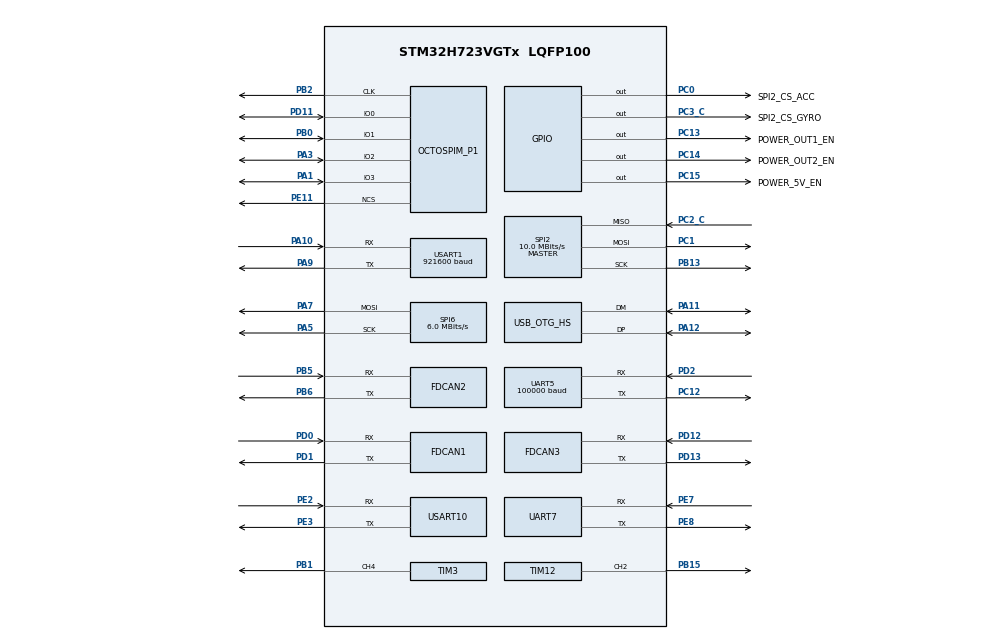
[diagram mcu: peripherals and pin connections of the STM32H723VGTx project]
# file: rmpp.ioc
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CORTEX_M7.CPU_DCache=Enabled
CORTEX_M7.CPU_ICache=Enabled
CORTEX_M7.default_mode_Activation=0
Dma.DMA_GENERATOR0.7.Direction=DMA_MEMORY_TO_PERIPH
Dma.DMA_GENERATOR0.7.EventEnable=DISABLE
Dma.DMA_GENERATOR0.7.FIFOMode=DMA_FIFOMODE_DISABLE
Dma.DMA_GENERATOR0.7.Instance=DMA2_Stream0
Dma.DMA_GENERATOR0.7.MemDataAlignment=DMA_MDATAALIGN_HALFWORD
Dma.DMA_GENERATOR0.7.MemInc=DMA_MINC_ENABLE
Dma.DMA_GENERATOR0.7.Mode=DMA_CIRCULAR
Dma.DMA_GENERATOR0.7.PeriphDataAlignment=DMA_PDATAALIGN_HALFWORD
Dma.DMA_GENERATOR0.7.PeriphInc=DMA_PINC_DISABLE
Dma.DMA_GENERATOR0.7.Polarity=HAL_DMAMUX_REQ_GEN_RISING
Dma.DMA_GENERATOR0.7.Priority=DMA_PRIORITY_LOW
Dma.DMA_GENERATOR0.7.RequestNumber=1
Dma.DMA_GENERATOR0.7.SignalID=HAL_DMAMUX1_REQ_GEN_TIM12_TRGO
Dma.DMA_GENERATOR0.7.SyncEnable=DISABLE
Dma.DMA_GENERATOR0.7.SyncPolarity=HAL_DMAMUX_SYNC_NO_EVENT
Dma.DMA_GENERATOR0.7.SyncRequestNumber=1
Dma.DMA_GENERATOR0.7.SyncSignalID=NONE
Dma.Request0=UART5_RX
Dma.Request1=USART1_RX
Dma.Request2=USART1_TX
Dma.Request3=UART7_RX
Dma.Request4=UART7_TX
Dma.Request5=USART10_RX
Dma.Request6=USART10_TX
Dma.Request7=DMA_GENERATOR0
Dma.UART5_RX.0.Direction=DMA_PERIPH_TO_MEMORY
Dma.UART5_RX.0.EventEnable=DISABLE
Dma.UART5_RX.0.FIFOMode=DMA_FIFOMODE_DISABLE
Dma.UART5_RX.0.Instance=DMA1_Stream0
Dma.UART5_RX.0.MemDataAlignment=DMA_MDATAALIGN_BYTE
Dma.UART5_RX.0.MemInc=DMA_MINC_ENABLE
Dma.UART5_RX.0.Mode=DMA_NORMAL
Dma.UART5_RX.0.PeriphDataAlignment=DMA_PDATAALIGN_BYTE
Dma.UART5_RX.0.PeriphInc=DMA_PINC_DISABLE
Dma.UART5_RX.0.Polarity=HAL_DMAMUX_REQ_GEN_RISING
Dma.UART5_RX.0.Priority=DMA_PRIORITY_LOW
Dma.UART5_RX.0.RequestNumber=1
Dma.UART5_RX.0.SignalID=NONE
Dma.UART5_RX.0.SyncEnable=DISABLE
Dma.UART5_RX.0.SyncPolarity=HAL_DMAMUX_SYNC_NO_EVENT
Dma.UART5_RX.0.SyncRequestNumber=1
Dma.UART5_RX.0.SyncSignalID=NONE
Dma.UART7_RX.3.Direction=DMA_PERIPH_TO_MEMORY
Dma.UART7_RX.3.EventEnable=DISABLE
Dma.UART7_RX.3.FIFOMode=DMA_FIFOMODE_DISABLE
Dma.UART7_RX.3.Instance=DMA1_Stream3
Dma.UART7_RX.3.MemDataAlignment=DMA_MDATAALIGN_BYTE
Dma.UART7_RX.3.MemInc=DMA_MINC_ENABLE
Dma.UART7_RX.3.Mode=DMA_NORMAL
Dma.UART7_RX.3.PeriphDataAlignment=DMA_PDATAALIGN_BYTE
Dma.UART7_RX.3.PeriphInc=DMA_PINC_DISABLE
Dma.UART7_RX.3.Polarity=HAL_DMAMUX_REQ_GEN_RISING
Dma.UART7_RX.3.Priority=DMA_PRIORITY_LOW
Dma.UART7_RX.3.RequestNumber=1
Dma.UART7_RX.3.SignalID=NONE
Dma.UART7_RX.3.SyncEnable=DISABLE
Dma.UART7_RX.3.SyncPolarity=HAL_DMAMUX_SYNC_NO_EVENT
Dma.UART7_RX.3.SyncRequestNumber=1
Dma.UART7_RX.3.SyncSignalID=NONE
Dma.UART7_TX.4.Direction=DMA_MEMORY_TO_PERIPH
Dma.UART7_TX.4.EventEnable=DISABLE
Dma.UART7_TX.4.FIFOMode=DMA_FIFOMODE_DISABLE
Dma.UART7_TX.4.Instance=DMA1_Stream4
Dma.UART7_TX.4.MemDataAlignment=DMA_MDATAALIGN_BYTE
Dma.UART7_TX.4.MemInc=DMA_MINC_ENABLE
Dma.UART7_TX.4.Mode=DMA_NORMAL
Dma.UART7_TX.4.PeriphDataAlignment=DMA_PDATAALIGN_BYTE
Dma.UART7_TX.4.PeriphInc=DMA_PINC_DISABLE
Dma.UART7_TX.4.Polarity=HAL_DMAMUX_REQ_GEN_RISING
Dma.UART7_TX.4.Priority=DMA_PRIORITY_LOW
Dma.UART7_TX.4.RequestNumber=1
Dma.UART7_TX.4.SignalID=NONE
Dma.UART7_TX.4.SyncEnable=DISABLE
Dma.UART7_TX.4.SyncPolarity=HAL_DMAMUX_SYNC_NO_EVENT
Dma.UART7_TX.4.SyncRequestNumber=1
Dma.UART7_TX.4.SyncSignalID=NONE
Dma.USART10_RX.5.Direction=DMA_PERIPH_TO_MEMORY
Dma.USART10_RX.5.EventEnable=DISABLE
Dma.USART10_RX.5.FIFOMode=DMA_FIFOMODE_DISABLE
Dma.USART10_RX.5.Instance=DMA1_Stream5
Dma.USART10_RX.5.MemDataAlignment=DMA_MDATAALIGN_BYTE
Dma.USART10_RX.5.MemInc=DMA_MINC_ENABLE
Dma.USART10_RX.5.Mode=DMA_NORMAL
Dma.USART10_RX.5.PeriphDataAlignment=DMA_PDATAALIGN_BYTE
Dma.USART10_RX.5.PeriphInc=DMA_PINC_DISABLE
Dma.USART10_RX.5.Polarity=HAL_DMAMUX_REQ_GEN_RISING
Dma.USART10_RX.5.Priority=DMA_PRIORITY_LOW
Dma.USART10_RX.5.RequestNumber=1
Dma.USART10_RX.5.SignalID=NONE
Dma.USART10_RX.5.SyncEnable=DISABLE
Dma.USART10_RX.5.SyncPolarity=HAL_DMAMUX_SYNC_NO_EVENT
Dma.USART10_RX.5.SyncRequestNumber=1
Dma.USART10_RX.5.SyncSignalID=NONE
Dma.USART10_TX.6.Direction=DMA_MEMORY_TO_PERIPH
Dma.USART10_TX.6.EventEnable=DISABLE
Dma.USART10_TX.6.FIFOMode=DMA_FIFOMODE_DISABLE
Dma.USART10_TX.6.Instance=DMA1_Stream6
Dma.USART10_TX.6.MemDataAlignment=DMA_MDATAALIGN_BYTE
Dma.USART10_TX.6.MemInc=DMA_MINC_ENABLE
Dma.USART10_TX.6.Mode=DMA_NORMAL
Dma.USART10_TX.6.PeriphDataAlignment=DMA_PDATAALIGN_BYTE
Dma.USART10_TX.6.PeriphInc=DMA_PINC_DISABLE
Dma.USART10_TX.6.Polarity=HAL_DMAMUX_REQ_GEN_RISING
Dma.USART10_TX.6.Priority=DMA_PRIORITY_LOW
Dma.USART10_TX.6.RequestNumber=1
Dma.USART10_TX.6.SignalID=NONE
Dma.USART10_TX.6.SyncEnable=DISABLE
Dma.USART10_TX.6.SyncPolarity=HAL_DMAMUX_SYNC_NO_EVENT
Dma.USART10_TX.6.SyncRequestNumber=1
Dma.USART10_TX.6.SyncSignalID=NONE
Dma.USART1_RX.1.Direction=DMA_PERIPH_TO_MEMORY
Dma.USART1_RX.1.EventEnable=DISABLE
Dma.USART1_RX.1.FIFOMode=DMA_FIFOMODE_DISABLE
Dma.USART1_RX.1.Instance=DMA1_Stream1
Dma.USART1_RX.1.MemDataAlignment=DMA_MDATAALIGN_BYTE
Dma.USART1_RX.1.MemInc=DMA_MINC_ENABLE
Dma.USART1_RX.1.Mode=DMA_NORMAL
Dma.USART1_RX.1.PeriphDataAlignment=DMA_PDATAALIGN_BYTE
Dma.USART1_RX.1.PeriphInc=DMA_PINC_DISABLE
Dma.USART1_RX.1.Polarity=HAL_DMAMUX_REQ_GEN_RISING
Dma.USART1_RX.1.Priority=DMA_PRIORITY_LOW
Dma.USART1_RX.1.RequestNumber=1
Dma.USART1_RX.1.SignalID=NONE
Dma.USART1_RX.1.SyncEnable=DISABLE
Dma.USART1_RX.1.SyncPolarity=HAL_DMAMUX_SYNC_NO_EVENT
Dma.USART1_RX.1.SyncRequestNumber=1
Dma.USART1_RX.1.SyncSignalID=NONE
Dma.USART1_TX.2.Direction=DMA_MEMORY_TO_PERIPH
Dma.USART1_TX.2.EventEnable=DISABLE
Dma.USART1_TX.2.FIFOMode=DMA_FIFOMODE_DISABLE
Dma.USART1_TX.2.Instance=DMA1_Stream2
Dma.USART1_TX.2.MemDataAlignment=DMA_MDATAALIGN_BYTE
Dma.USART1_TX.2.MemInc=DMA_MINC_ENABLE
Dma.USART1_TX.2.Mode=DMA_NORMAL
Dma.USART1_TX.2.PeriphDataAlignment=DMA_PDATAALIGN_BYTE
Dma.USART1_TX.2.PeriphInc=DMA_PINC_DISABLE
Dma.USART1_TX.2.Polarity=HAL_DMAMUX_REQ_GEN_RISING
Dma.USART1_TX.2.Priority=DMA_PRIORITY_LOW
Dma.USART1_TX.2.RequestNumber=1
Dma.USART1_TX.2.SignalID=NONE
Dma.USART1_TX.2.SyncEnable=DISABLE
Dma.USART1_TX.2.SyncPolarity=HAL_DMAMUX_SYNC_NO_EVENT
Dma.USART1_TX.2.SyncRequestNumber=1
Dma.USART1_TX.2.SyncSignalID=NONE
FDCAN1.AutoRetransmission=ENABLE
FDCAN1.CalculateBaudRateNominal=1000000
FDCAN1.CalculateTimeBitNominal=1000
FDCAN1.CalculateTimeQuantumNominal=40.0
FDCAN1.ExtFiltersNbr=1
FDCAN1.MessageRAMOffset=0x000
FDCAN1.NominalPrescaler=5
FDCAN1.NominalSyncJumpWidth=5
FDCAN1.NominalTimeSeg1=19
FDCAN1.NominalTimeSeg2=5
FDCAN1.RxFifo0ElmtsNbr=32
FDCAN1.StdFiltersNbr=1
FDCAN1.TxBuffersNbr=0
FDCAN1.TxFifoQueueElmtsNbr=32
FDCAN1.TxFifoQueueMode=FDCAN_TX_FIFO_OPERATION
FDCAN2.AutoRetransmission=ENABLE
FDCAN2.CalculateBaudRateNominal=1000000
FDCAN2.CalculateTimeBitNominal=1000
FDCAN2.CalculateTimeQuantumNominal=40.0
FDCAN2.ExtFiltersNbr=1
FDCAN2.MessageRAMOffset=0x358
FDCAN2.NominalPrescaler=5
FDCAN2.NominalSyncJumpWidth=5
FDCAN2.NominalTimeSeg1=19
FDCAN2.NominalTimeSeg2=5
FDCAN2.RxFifo0ElmtsNbr=32
FDCAN2.StdFiltersNbr=1
FDCAN2.TxBuffersNbr=0
FDCAN2.TxFifoQueueElmtsNbr=32
FDCAN2.TxFifoQueueMode=FDCAN_TX_FIFO_OPERATION
FDCAN3.AutoRetransmission=ENABLE
FDCAN3.CalculateBaudRateNominal=1000000
FDCAN3.CalculateTimeBitNominal=1000
FDCAN3.CalculateTimeQuantumNominal=40.0
FDCAN3.ExtFiltersNbr=1
FDCAN3.MessageRAMOffset=0x6B0
FDCAN3.NominalPrescaler=5
FDCAN3.NominalSyncJumpWidth=5
FDCAN3.NominalTimeSeg1=19
FDCAN3.NominalTimeSeg2=5
FDCAN3.RxFifo0ElmtsNbr=32
FDCAN3.StdFiltersNbr=1
FDCAN3.TxFifoQueueElmtsNbr=32
FDCAN3.TxFifoQueueMode=FDCAN_TX_FIFO_OPERATION
Mcu.Family=STM32H7
Mcu.Name=STM32H723VGTx
Mcu.Package=LQFP100
NVIC.DMA1_Stream0_IRQn=true\:0\:0\:false\:false\:true\:false\:true\:true
NVIC.DMA1_Stream1_IRQn=true\:0\:0\:false\:false\:true\:false\:true\:true
NVIC.DMA1_Stream2_IRQn=true\:0\:0\:false\:false\:true\:false\:true\:true
NVIC.DMA1_Stream3_IRQn=true\:0\:0\:false\:false\:true\:false\:true\:true
NVIC.DMA1_Stream4_IRQn=true\:0\:0\:false\:false\:true\:false\:true\:true
NVIC.DMA1_Stream5_IRQn=true\:0\:0\:false\:false\:true\:false\:true\:true
NVIC.DMA1_Stream6_IRQn=true\:0\:0\:false\:false\:true\:false\:true\:true
NVIC.DMA2_Stream0_IRQn=true\:15\:0\:true\:false\:true\:true\:true\:true
NVIC.DMAMUX1_OVR_IRQn=true\:0\:0\:false\:false\:true\:false\:true\:true
NVIC.FDCAN1_IT0_IRQn=true\:0\:0\:false\:false\:true\:true\:true\:true
NVIC.FDCAN2_IT0_IRQn=true\:0\:0\:false\:false\:true\:true\:true\:true
NVIC.FDCAN3_IT0_IRQn=true\:0\:0\:false\:false\:true\:true\:true\:true
NVIC.PriorityGroup=NVIC_PRIORITYGROUP_4
NVIC.UART5_IRQn=true\:0\:0\:false\:false\:true\:true\:true\:true
NVIC.UART7_IRQn=true\:0\:0\:false\:false\:true\:true\:true\:true
NVIC.USART10_IRQn=true\:0\:0\:false\:false\:true\:true\:true\:true
NVIC.USART1_IRQn=true\:0\:0\:false\:false\:true\:true\:true\:true
OCTOSPI1.ChipSelectHighTime=3
OCTOSPI1.ClockMode=HAL_OSPI_CLOCK_MODE_3
OCTOSPI1.ClockPrescaler=6
OCTOSPI1.DeviceSize=23
OCTOSPI1.FifoThreshold=8
OCTOSPI1.SampleShifting=HAL_OSPI_SAMPLE_SHIFTING_HALFCYCLE
PA1.Mode=OCTOSPI1_IOL_Port1L
PA1.Signal=OCTOSPIM_P1_IO3
PA10.Mode=Asynchronous
PA10.Signal=USART1_RX
PA11.Mode=Device_Only_FS
PA11.Signal=USB_OTG_HS_DM
PA12.Mode=Device_Only_FS
PA12.Signal=USB_OTG_HS_DP
PA13(JTMS/SWDIO).Mode=Serial_Wire
PA13(JTMS/SWDIO).Signal=DEBUG_JTMS-SWDIO
PA14(JTCK/SWCLK).Mode=Serial_Wire
PA14(JTCK/SWCLK).Signal=DEBUG_JTCK-SWCLK
PA3.Mode=OCTOSPI1_IOL_Port1L
PA3.Signal=OCTOSPIM_P1_IO2
PA5.Mode=TX_Only_Simplex_Unidirect_Master
PA5.Signal=SPI6_SCK
PA7.Mode=TX_Only_Simplex_Unidirect_Master
PA7.Signal=SPI6_MOSI
PA9.Mode=Asynchronous
PA9.Signal=USART1_TX
PB0.Mode=OCTOSPI1_IOL_Port1L
PB0.Signal=OCTOSPIM_P1_IO1
PB1.Signal=S_TIM3_CH4
PB13.Mode=Full_Duplex_Master
PB13.Signal=SPI2_SCK
PB15.Signal=S_TIM12_CH2
PB2.Mode=O1_P1_CLK
PB2.Signal=OCTOSPIM_P1_CLK
PB5.Mode=FDCAN_Activate
PB5.Signal=FDCAN2_RX
PB6.Mode=FDCAN_Activate
PB6.Signal=FDCAN2_TX
PC0.GPIO_Label=SPI2_CS_ACC
PC0.PinState=GPIO_PIN_SET
PC0.Signal=GPIO_Output
PC1.Mode=Full_Duplex_Master
PC1.Signal=SPI2_MOSI
PC12.Mode=Asynchronous
PC12.Signal=UART5_TX
PC13.GPIO_Label=POWER_OUT1_EN
PC13.PinState=GPIO_PIN_RESET
PC13.Signal=GPIO_Output
PC14-OSC32_IN.GPIO_Label=POWER_OUT2_EN
PC14-OSC32_IN.Signal=GPIO_Output
PC15-OSC32_OUT.GPIO_Label=POWER_5V_EN
PC15-OSC32_OUT.Signal=GPIO_Output
PC2_C.Mode=Full_Duplex_Master
PC2_C.Signal=SPI2_MISO
PC3_C.GPIO_Label=SPI2_CS_GYRO
PC3_C.PinState=GPIO_PIN_SET
PC3_C.Signal=GPIO_Output
PD0.Mode=FDCAN_Activate
PD0.Signal=FDCAN1_RX
PD1.Mode=FDCAN_Activate
PD1.Signal=FDCAN1_TX
PD11.Mode=OCTOSPI1_IOL_Port1L
PD11.Signal=OCTOSPIM_P1_IO0
PD12.Mode=FDCAN_Activate
PD12.Signal=FDCAN3_RX
PD13.Mode=FDCAN_Activate
PD13.Signal=FDCAN3_TX
PD2.Mode=Asynchronous
PD2.Signal=UART5_RX
PE11.Mode=OCTOSPI1_Port1_NCS
PE11.Signal=OCTOSPIM_P1_NCS
PE2.Mode=Asynchronous
PE2.Signal=USART10_RX
PE3.Mode=Asynchronous
PE3.Signal=USART10_TX
PE7.Mode=Asynchronous
PE7.Signal=UART7_RX
PE8.Mode=Asynchronous
PE8.Signal=UART7_TX
PH0-OSC_IN.Mode=HSE-External-Oscillator
PH0-OSC_IN.Signal=RCC_OSC_IN
PH1-OSC_OUT.Mode=HSE-External-Oscillator
PH1-OSC_OUT.Signal=RCC_OSC_OUT
ProjectManager.HeapSize=0x200
ProjectManager.StackSize=0x400
ProjectManager.TargetToolchain=CMake
RCC.ADCFreq_Value=125000000
RCC.APB1Freq_Value=130000000
RCC.APB2Freq_Value=130000000
RCC.APB3Freq_Value=130000000
RCC.APB4Freq_Value=130000000
RCC.CortexFreq_Value=520000000
RCC.D1PPRE=RCC_APB3_DIV2
RCC.D2PPRE1=RCC_APB1_DIV2
RCC.D2PPRE2=RCC_APB2_DIV2
RCC.D3PPRE=RCC_APB4_DIV2
RCC.DIVM1=3
RCC.DIVM2=4
RCC.DIVM3=2
RCC.DIVN1=65
RCC.DIVN2=125
RCC.DIVN3=40
RCC.DIVP1=1
RCC.DIVP2=6
RCC.DIVP3=6
RCC.DIVQ1=1
RCC.DIVQ2=6
RCC.DIVQ3=10
RCC.DIVR1=1
RCC.FDCANCLockSelection=RCC_FDCANCLKSOURCE_PLL2
RCC.HCLKFreq_Value=260000000
RCC.HPRE=RCC_HCLK_DIV2
RCC.HSE_VALUE=24000000
RCC.PLL2FRACN=0
RCC.PLL3FRACN=0
RCC.PLLFRACN=0
RCC.PLLSourceVirtual=RCC_PLLSOURCE_HSE
RCC.PWR_Regulator_Voltage_Scale=PWR_REGULATOR_VOLTAGE_SCALE0
RCC.SPI123CLockSelection=RCC_SPI123CLKSOURCE_PLL3
RCC.SPI6CLockSelection=RCC_SPI6CLKSOURCE_HSE
RCC.SYSCLKFreq_VALUE=520000000
RCC.SYSCLKSource=RCC_SYSCLKSOURCE_PLLCLK
RCC.USBCLockSelection=RCC_USBCLKSOURCE_PLL3
RCC.USBFreq_Value=48000000
SH.S_TIM12_CH2.0=TIM12_CH2,PWM Generation2 CH2
SH.S_TIM3_CH4.0=TIM3_CH4,PWM Generation4 CH4
SPI2.BaudRatePrescaler=SPI_BAUDRATEPRESCALER_8
SPI2.CLKPhase=SPI_PHASE_2EDGE
SPI2.CLKPolarity=SPI_POLARITY_HIGH
SPI2.CalculateBaudRate=10.0 MBits/s
SPI2.DataSize=SPI_DATASIZE_8BIT
SPI2.Direction=SPI_DIRECTION_2LINES
SPI2.MasterKeepIOState=SPI_MASTER_KEEP_IO_STATE_ENABLE
SPI2.Mode=SPI_MODE_MASTER
SPI2.VirtualType=VM_MASTER
SPI6.BaudRatePrescaler=SPI_BAUDRATEPRESCALER_4
SPI6.CLKPhase=SPI_PHASE_2EDGE
SPI6.CalculateBaudRate=6.0 MBits/s
SPI6.DataSize=SPI_DATASIZE_8BIT
SPI6.Direction=SPI_DIRECTION_2LINES_TXONLY
SPI6.MasterKeepIOState=SPI_MASTER_KEEP_IO_STATE_ENABLE
SPI6.Mode=SPI_MODE_MASTER
SPI6.VirtualType=VM_MASTER
TIM12.AutoReloadPreload=TIM_AUTORELOAD_PRELOAD_ENABLE
TIM12.Channel-PWM\ Generation2\ CH2=TIM_CHANNEL_2
TIM12.TIM_MasterOutputTrigger=TIM_TRGO_UPDATE
TIM3.AutoReloadPreload=TIM_AUTORELOAD_PRELOAD_ENABLE
TIM3.Channel-PWM\ Generation4\ CH4=TIM_CHANNEL_4
UART5.BaudRate=100000
UART5.Mode=MODE_RX
UART5.Parity=PARITY_EVEN
UART5.StopBits=UART_STOPBITS_2
UART5.WordLength=WORDLENGTH_9B
USART1.BaudRate=921600
USART1.VirtualMode-Asynchronous=VM_ASYNC
USART10.VirtualMode=VM_ASYNC
USB_OTG_HS.VirtualMode-Device_Only_FS=Device_Only_FS
VP_MEMORYMAP_VS_MEMORYMAP.Mode=CurAppReg
VP_OCTOSPI1_VS_quad.Mode=quad_mode
VP_TIM12_VS_ClockSourceINT.Mode=Internal
VP_TIM3_VS_ClockSourceINT.Mode=Internal
board=custom

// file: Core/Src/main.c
/* USER CODE BEGIN Header */
/**
  ******************************************************************************
  * @file           : main.c
  * @brief          : Main program body
  ******************************************************************************
  * @attention
  *
  * Copyright (c) 2026 STMicroelectronics.
  * All rights reserved.
  *
  * This software is licensed under terms that can be found in the LICENSE file
  * in the root directory of this software component.
  * If no LICENSE file comes with this software, it is provided AS-IS.
  *
  ******************************************************************************
  */
/* USER CODE END Header */
#include "main.h"
#include "dma.h"
#include "fdcan.h"
#include "octospi.h"
#include "spi.h"
#include "tim.h"
#include "usart.h"
#include "gpio.h"

void SystemClock_Config(void);
void PeriphCommonClock_Config(void);

int main(void)
{

  /* Enable the CPU Cache */

  /* Enable I-Cache---------------------------------------------------------*/
  SCB_EnableICache();

  /* Enable D-Cache---------------------------------------------------------*/
  SCB_EnableDCache();

  /* MCU Configuration--------------------------------------------------------*/

  /* Reset of all peripherals, Initializes the Flash interface and the Systick. */
  HAL_Init();

  /* Configure the system clock */
  SystemClock_Config();

  /* Configure the peripherals common clocks */
  PeriphCommonClock_Config();

  /* Initialize all configured peripherals */
  MX_GPIO_Init();
  MX_DMA_Init();
  MX_TIM3_Init();
  MX_TIM12_Init();
  MX_FDCAN1_Init();
  MX_FDCAN2_Init();
  MX_FDCAN3_Init();
  MX_SPI2_Init();
  MX_SPI6_Init();
  MX_USART1_UART_Init();
  MX_UART5_Init();
  MX_UART7_Init();
  MX_USART10_UART_Init();
  MX_OCTOSPI1_Init();
  /* USER CODE BEGIN 2 */
  extern void bsp_init();
  extern void app_main();

  bsp_init();
  app_main();
  /* USER CODE END 2 */

  /* Infinite loop */
  while (1)
  {

  }
}

void SystemClock_Config(void)
{
  RCC_OscInitTypeDef RCC_OscInitStruct = {0};
  RCC_ClkInitTypeDef RCC_ClkInitStruct = {0};

  /** Supply configuration update enable
  */
  HAL_PWREx_ConfigSupply(PWR_LDO_SUPPLY);

  /** Configure the main internal regulator output voltage
  */
  __HAL_PWR_VOLTAGESCALING_CONFIG(PWR_REGULATOR_VOLTAGE_SCALE0);

  while(!__HAL_PWR_GET_FLAG(PWR_FLAG_VOSRDY)) {}

  /** Initializes the RCC Oscillators according to the specified parameters
  * in the RCC_OscInitTypeDef structure.
  */
  RCC_OscInitStruct.OscillatorType = RCC_OSCILLATORTYPE_HSE;
  RCC_OscInitStruct.HSEState = RCC_HSE_ON;
  RCC_OscInitStruct.PLL.PLLState = RCC_PLL_ON;
  RCC_OscInitStruct.PLL.PLLSource = RCC_PLLSOURCE_HSE;
  RCC_OscInitStruct.PLL.PLLM = 3;
  RCC_OscInitStruct.PLL.PLLN = 65;
  RCC_OscInitStruct.PLL.PLLP = 1;
  RCC_OscInitStruct.PLL.PLLQ = 1;
  RCC_OscInitStruct.PLL.PLLR = 1;
  RCC_OscInitStruct.PLL.PLLRGE = RCC_PLL1VCIRANGE_3;
  RCC_OscInitStruct.PLL.PLLVCOSEL = RCC_PLL1VCOWIDE;
  RCC_OscInitStruct.PLL.PLLFRACN = 0;
  if (HAL_RCC_OscConfig(&RCC_OscInitStruct) != HAL_OK)
  {
    Error_Handler();
  }

  /** Initializes the CPU, AHB and APB buses clocks
  */
  RCC_ClkInitStruct.ClockType = RCC_CLOCKTYPE_HCLK|RCC_CLOCKTYPE_SYSCLK
                              |RCC_CLOCKTYPE_PCLK1|RCC_CLOCKTYPE_PCLK2
                              |RCC_CLOCKTYPE_D3PCLK1|RCC_CLOCKTYPE_D1PCLK1;
  RCC_ClkInitStruct.SYSCLKSource = RCC_SYSCLKSOURCE_PLLCLK;
  RCC_ClkInitStruct.SYSCLKDivider = RCC_SYSCLK_DIV1;
  RCC_ClkInitStruct.AHBCLKDivider = RCC_HCLK_DIV2;
  RCC_ClkInitStruct.APB3CLKDivider = RCC_APB3_DIV2;
  RCC_ClkInitStruct.APB1CLKDivider = RCC_APB1_DIV2;
  RCC_ClkInitStruct.APB2CLKDivider = RCC_APB2_DIV2;
  RCC_ClkInitStruct.APB4CLKDivider = RCC_APB4_DIV2;

  if (HAL_RCC_ClockConfig(&RCC_ClkInitStruct, FLASH_LATENCY_3) != HAL_OK)
  {
    Error_Handler();
  }
}

void PeriphCommonClock_Config(void)
{
  RCC_PeriphCLKInitTypeDef PeriphClkInitStruct = {0};

  /** Initializes the peripherals clock
  */
  PeriphClkInitStruct.PeriphClockSelection = RCC_PERIPHCLK_USB|RCC_PERIPHCLK_SPI2
                              |RCC_PERIPHCLK_FDCAN;
  PeriphClkInitStruct.PLL2.PLL2M = 4;
  PeriphClkInitStruct.PLL2.PLL2N = 125;
  PeriphClkInitStruct.PLL2.PLL2P = 6;
  PeriphClkInitStruct.PLL2.PLL2Q = 6;
  PeriphClkInitStruct.PLL2.PLL2R = 2;
  PeriphClkInitStruct.PLL2.PLL2RGE = RCC_PLL2VCIRANGE_2;
  PeriphClkInitStruct.PLL2.PLL2VCOSEL = RCC_PLL2VCOWIDE;
  PeriphClkInitStruct.PLL2.PLL2FRACN = 0;
  PeriphClkInitStruct.PLL3.PLL3M = 2;
  PeriphClkInitStruct.PLL3.PLL3N = 40;
  PeriphClkInitStruct.PLL3.PLL3P = 6;
  PeriphClkInitStruct.PLL3.PLL3Q = 10;
  PeriphClkInitStruct.PLL3.PLL3R = 2;
  PeriphClkInitStruct.PLL3.PLL3RGE = RCC_PLL3VCIRANGE_3;
  PeriphClkInitStruct.PLL3.PLL3VCOSEL = RCC_PLL3VCOWIDE;
  PeriphClkInitStruct.PLL3.PLL3FRACN = 0;
  PeriphClkInitStruct.Spi123ClockSelection = RCC_SPI123CLKSOURCE_PLL3;
  PeriphClkInitStruct.FdcanClockSelection = RCC_FDCANCLKSOURCE_PLL2;
  PeriphClkInitStruct.UsbClockSelection = RCC_USBCLKSOURCE_PLL3;
  if (HAL_RCCEx_PeriphCLKConfig(&PeriphClkInitStruct) != HAL_OK)
  {
    Error_Handler();
  }
}

void Error_Handler(void)
{
  __disable_irq();
  while (1)
  {
  }
}
